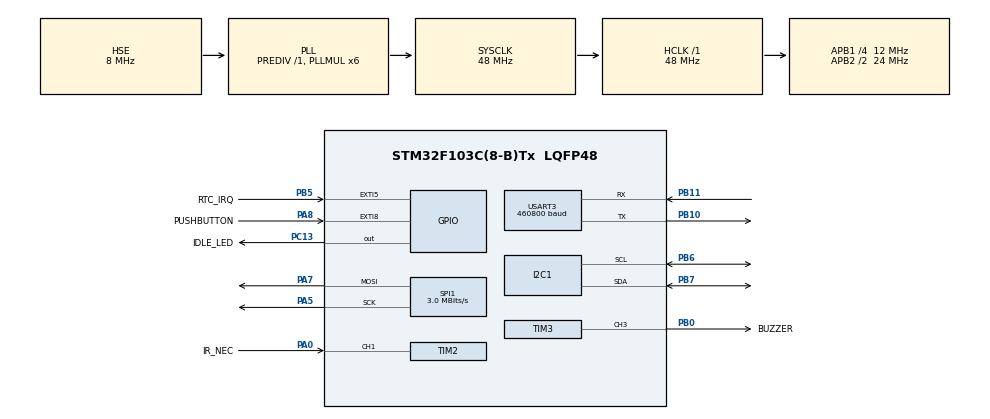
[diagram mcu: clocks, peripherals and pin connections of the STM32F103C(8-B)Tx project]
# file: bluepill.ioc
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Mcu.Family=STM32F1
NVIC.USART3_IRQn=true\:7\:0\:true\:false\:true\:true\:true
Dma.SPI1_TX.0.MemInc=DMA_MINC_ENABLE
Dma.SPI1_TX.0.PeriphInc=DMA_PINC_DISABLE
TIM2.Channel-Input_Capture1_from_TI1=TIM_CHANNEL_1
NVIC.DMA1_Channel5_IRQn=true\:4\:0\:true\:false\:true\:false\:true
SPI1.VirtualType=VM_MASTER
PB10.Mode=Asynchronous
VP_IWDG_VS_IWDG.Mode=IWDG_Activate
PB0.GPIO_Label=BUZZER
PB11.Signal=USART3_RX
RCC.SYSCLKSource=RCC_SYSCLKSOURCE_PLLCLK
ProjectManager.StackSize=0x400
PD1-OSC_OUT.Signal=RCC_OSC_OUT
NVIC.DMA1_Channel3_IRQn=true\:5\:0\:true\:false\:true\:false\:true
USART3.BaudRate=460800
TIM2.ICPolarity_CH1=TIM_INPUTCHANNELPOLARITY_FALLING
Dma.TIM2_CH1.1.Direction=DMA_PERIPH_TO_MEMORY
SPI1.Direction=SPI_DIRECTION_2LINES
RCC.HCLKFreq_Value=48000000
RCC.APB2TimFreq_Value=48000000
TIM3.Period=28-1
PB6.Signal=I2C1_SCL
PB6.Mode=I2C
SPI1.CalculateBaudRate=3.0 MBits/s
Dma.TIM3_CH3.2.MemDataAlignment=DMA_MDATAALIGN_BYTE
RCC.AHBFreq_Value=48000000
RCC.PLLMUL=RCC_PLL_MUL6
PA14.Mode=Serial_Wire
TIM3.Prescaler=4-1
NVIC.TIM2_IRQn=true\:3\:0\:true\:false\:true\:true\:true
PA0-WKUP.GPIO_Mode=GPIO_MODE_INPUT
PB7.Signal=I2C1_SDA
PA8.Signal=GPXTI8
Dma.TIM3_CH3.2.MemInc=DMA_MINC_ENABLE
Dma.SPI1_TX.0.Mode=DMA_NORMAL
Mcu.Package=LQFP48
TIM2.Prescaler=23
Dma.TIM2_CH1.1.MemDataAlignment=DMA_MDATAALIGN_WORD
PA8.GPIO_ModeDefaultEXTI=GPIO_MODE_IT_FALLING
Dma.TIM2_CH1.1.Priority=DMA_PRIORITY_LOW
RCC.APB2CLKDivider=RCC_HCLK_DIV2
PB5.GPIO_Label=RTC_IRQ
Dma.Request2=TIM3_CH3
Dma.Request1=TIM2_CH1
Dma.TIM3_CH3.2.Mode=DMA_NORMAL
RCC.APB1TimFreq_Value=24000000
Dma.TIM2_CH1.1.PeriphDataAlignment=DMA_PDATAALIGN_WORD
Dma.Request0=SPI1_TX
SPI1.BaudRatePrescaler=SPI_BAUDRATEPRESCALER_8
VP_TIM3_VS_ClockSourceINT.Mode=Internal
PA5.Mode=TX_Only_Simplex_Unidirect_Master
RCC.PLLSourceVirtual=RCC_PLLSOURCE_HSE
Dma.TIM2_CH1.1.MemInc=DMA_MINC_ENABLE
Dma.TIM3_CH3.2.Direction=DMA_MEMORY_TO_PERIPH
PA7.Mode=TX_Only_Simplex_Unidirect_Master
PD1-OSC_OUT.Mode=HSE-External-Oscillator
VP_TIM2_VS_ControllerModeReset.Mode=Reset Mode
PC13-TAMPER-RTC.Signal=GPIO_Output
PD0-OSC_IN.Signal=RCC_OSC_IN
RCC.APB1CLKDivider=RCC_HCLK_DIV4
SH.S_TIM3_CH3.0=TIM3_CH3,PWM Generation3 CH3
PA0-WKUP.GPIO_Label=IR_NEC
PA0-WKUP.Signal=S_TIM2_CH1_ETR
PA13.Signal=SYS_JTMS-SWDIO
TIM3.Channel-PWM\ Generation3\ CH3=TIM_CHANNEL_3
PA8.GPIO_Label=PUSHBUTTON
Dma.TIM2_CH1.1.Instance=DMA1_Channel5
PB11.Mode=Asynchronous
NVIC.DMA1_Channel2_IRQn=true\:0\:0\:false\:false\:true\:false\:true
ProjectManager.TargetToolchain=Makefile
I2C1.I2C_Mode=I2C_Fast
Dma.SPI1_TX.0.PeriphDataAlignment=DMA_PDATAALIGN_BYTE
Dma.SPI1_TX.0.Direction=DMA_MEMORY_TO_PERIPH
TIM2.ICFilter_CH1=4
RCC.USBFreq_Value=48000000
Dma.TIM3_CH3.2.Instance=DMA1_Channel2
PD0-OSC_IN.Mode=HSE-External-Oscillator
PB10.Signal=USART3_TX
PA5.Signal=SPI1_SCK
board=custom
PB0.GPIO_ModeDefaultPP=GPIO_MODE_AF_PP
PC13-TAMPER-RTC.GPIO_Label=IDLE_LED
RCC.APB2Freq_Value=24000000
Dma.TIM2_CH1.1.PeriphInc=DMA_PINC_DISABLE
VP_TIM2_VS_ClockSourceINT.Mode=Internal
SPI1.Mode=SPI_MODE_MASTER
Dma.SPI1_TX.0.Instance=DMA1_Channel3
TIM2.Period=0xFFFF
PA13.Mode=Serial_Wire
Mcu.Name=STM32F103C(8-B)Tx
RCC.SYSCLKFreq_VALUE=48000000
PB5.Signal=GPXTI5
USART3.VirtualMode=VM_ASYNC
PB5.GPIO_PuPd=GPIO_PULLUP
Dma.TIM3_CH3.2.Priority=DMA_PRIORITY_LOW
PB7.Mode=I2C
SH.S_TIM2_CH1_ETR.1=TIM2_CH1,Input_Capture1_from_TI1
SH.S_TIM2_CH1_ETR.0=TIM2_CH1,TriggerSource_TI1FP1
NVIC.EXTI9_5_IRQn=true\:0\:0\:false\:false\:true\:true\:true
PA14.Signal=SYS_JTCK-SWCLK
ProjectManager.HeapSize=0x200
Dma.SPI1_TX.0.MemDataAlignment=DMA_MDATAALIGN_BYTE
Dma.SPI1_TX.0.Priority=DMA_PRIORITY_LOW
Dma.TIM2_CH1.1.Mode=DMA_NORMAL
PA8.GPIO_PuPd=GPIO_PULLUP
NVIC.PriorityGroup=NVIC_PRIORITYGROUP_4
IWDG.Prescaler=IWDG_PRESCALER_16
Dma.TIM3_CH3.2.PeriphInc=DMA_PINC_DISABLE
PA0-WKUP.GPIO_PuPd=GPIO_PULLUP
RCC.APB1Freq_Value=12000000
PB0.Signal=S_TIM3_CH3
Dma.TIM3_CH3.2.PeriphDataAlignment=DMA_PDATAALIGN_HALFWORD
PA7.Signal=SPI1_MOSI

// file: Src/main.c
/* USER CODE BEGIN Header */
/**
  ******************************************************************************
  * @file           : main.c
  * @brief          : Main program body
  ******************************************************************************
  * @attention
  *
  * <h2><center>&copy; Copyright (c) 2019 STMicroelectronics.
  * All rights reserved.</center></h2>
  *
  * This software component is licensed by ST under BSD 3-Clause license,
  * the "License"; You may not use this file except in compliance with the
  * License. You may obtain a copy of the License at:
  *                        opensource.org/licenses/BSD-3-Clause
  *
  ******************************************************************************
  */
/* USER CODE END Header */
#include "main.h"

/* USER CODE BEGIN Includes */
#include <string.h>
#include "esm/esm.h"
#include "board.h"
/* USER CODE END Includes */

I2C_HandleTypeDef hi2c1;

IWDG_HandleTypeDef hiwdg;

SPI_HandleTypeDef hspi1;
DMA_HandleTypeDef hdma_spi1_tx;

TIM_HandleTypeDef htim2;
TIM_HandleTypeDef htim3;
DMA_HandleTypeDef hdma_tim2_ch1;
DMA_HandleTypeDef hdma_tim3_ch3;

UART_HandleTypeDef huart3;

void SystemClock_Config(void);
static void MX_GPIO_Init(void);
static void MX_DMA_Init(void);
static void MX_SPI1_Init(void);
static void MX_USART3_UART_Init(void);
static void MX_I2C1_Init(void);
static void MX_TIM2_Init(void);
static void MX_TIM3_Init(void);
static void MX_IWDG_Init(void);

int main(void)
{

  /* MCU Configuration--------------------------------------------------------*/

  /* Reset of all peripherals, Initializes the Flash interface and the Systick. */
  HAL_Init();

  /* Configure the system clock */
  SystemClock_Config();

  /* Initialize all configured peripherals */
  MX_GPIO_Init();
  MX_DMA_Init();
  MX_SPI1_Init();
  MX_USART3_UART_Init();
  MX_I2C1_Init();
  MX_TIM2_Init();
  MX_TIM3_Init();
  MX_IWDG_Init();

  /* Infinite loop */
  /* USER CODE BEGIN WHILE */
  while (1)
  {
    esm_process();
    /* USER CODE END WHILE */

  }
}

void SystemClock_Config(void)
{
  RCC_OscInitTypeDef RCC_OscInitStruct = {0};
  RCC_ClkInitTypeDef RCC_ClkInitStruct = {0};

  /** Initializes the RCC Oscillators according to the specified parameters
  * in the RCC_OscInitTypeDef structure.
  */
  RCC_OscInitStruct.OscillatorType = RCC_OSCILLATORTYPE_LSI|RCC_OSCILLATORTYPE_HSE;
  RCC_OscInitStruct.HSEState = RCC_HSE_ON;
  RCC_OscInitStruct.HSEPredivValue = RCC_HSE_PREDIV_DIV1;
  RCC_OscInitStruct.HSIState = RCC_HSI_ON;
  RCC_OscInitStruct.LSIState = RCC_LSI_ON;
  RCC_OscInitStruct.PLL.PLLState = RCC_PLL_ON;
  RCC_OscInitStruct.PLL.PLLSource = RCC_PLLSOURCE_HSE;
  RCC_OscInitStruct.PLL.PLLMUL = RCC_PLL_MUL6;
  if (HAL_RCC_OscConfig(&RCC_OscInitStruct) != HAL_OK)
  {
    Error_Handler();
  }
  /** Initializes the CPU, AHB and APB buses clocks
  */
  RCC_ClkInitStruct.ClockType = RCC_CLOCKTYPE_HCLK|RCC_CLOCKTYPE_SYSCLK
                              |RCC_CLOCKTYPE_PCLK1|RCC_CLOCKTYPE_PCLK2;
  RCC_ClkInitStruct.SYSCLKSource = RCC_SYSCLKSOURCE_PLLCLK;
  RCC_ClkInitStruct.AHBCLKDivider = RCC_SYSCLK_DIV1;
  RCC_ClkInitStruct.APB1CLKDivider = RCC_HCLK_DIV4;
  RCC_ClkInitStruct.APB2CLKDivider = RCC_HCLK_DIV2;

  if (HAL_RCC_ClockConfig(&RCC_ClkInitStruct, FLASH_LATENCY_1) != HAL_OK)
  {
    Error_Handler();
  }
}

static void MX_I2C1_Init(void)
{

  hi2c1.Instance = I2C1;
  hi2c1.Init.ClockSpeed = 400000;
  hi2c1.Init.DutyCycle = I2C_DUTYCYCLE_2;
  hi2c1.Init.OwnAddress1 = 0;
  hi2c1.Init.AddressingMode = I2C_ADDRESSINGMODE_7BIT;
  hi2c1.Init.DualAddressMode = I2C_DUALADDRESS_DISABLE;
  hi2c1.Init.OwnAddress2 = 0;
  hi2c1.Init.GeneralCallMode = I2C_GENERALCALL_DISABLE;
  hi2c1.Init.NoStretchMode = I2C_NOSTRETCH_DISABLE;
  if (HAL_I2C_Init(&hi2c1) != HAL_OK)
  {
    Error_Handler();
  }

}

static void MX_IWDG_Init(void)
{

  hiwdg.Instance = IWDG;
  hiwdg.Init.Prescaler = IWDG_PRESCALER_16;
  hiwdg.Init.Reload = 4095;
  if (HAL_IWDG_Init(&hiwdg) != HAL_OK)
  {
    Error_Handler();
  }

}

static void MX_SPI1_Init(void)
{

  /* SPI1 parameter configuration*/
  hspi1.Instance = SPI1;
  hspi1.Init.Mode = SPI_MODE_MASTER;
  hspi1.Init.Direction = SPI_DIRECTION_2LINES;
  hspi1.Init.DataSize = SPI_DATASIZE_8BIT;
  hspi1.Init.CLKPolarity = SPI_POLARITY_LOW;
  hspi1.Init.CLKPhase = SPI_PHASE_1EDGE;
  hspi1.Init.NSS = SPI_NSS_SOFT;
  hspi1.Init.BaudRatePrescaler = SPI_BAUDRATEPRESCALER_8;
  hspi1.Init.FirstBit = SPI_FIRSTBIT_MSB;
  hspi1.Init.TIMode = SPI_TIMODE_DISABLE;
  hspi1.Init.CRCCalculation = SPI_CRCCALCULATION_DISABLE;
  hspi1.Init.CRCPolynomial = 10;
  if (HAL_SPI_Init(&hspi1) != HAL_OK)
  {
    Error_Handler();
  }

}

static void MX_TIM2_Init(void)
{

  TIM_ClockConfigTypeDef sClockSourceConfig = {0};
  TIM_SlaveConfigTypeDef sSlaveConfig = {0};
  TIM_MasterConfigTypeDef sMasterConfig = {0};
  TIM_IC_InitTypeDef sConfigIC = {0};

  htim2.Instance = TIM2;
  htim2.Init.Prescaler = 23;
  htim2.Init.CounterMode = TIM_COUNTERMODE_UP;
  htim2.Init.Period = 0xFFFF;
  htim2.Init.ClockDivision = TIM_CLOCKDIVISION_DIV1;
  htim2.Init.AutoReloadPreload = TIM_AUTORELOAD_PRELOAD_DISABLE;
  if (HAL_TIM_Base_Init(&htim2) != HAL_OK)
  {
    Error_Handler();
  }
  sClockSourceConfig.ClockSource = TIM_CLOCKSOURCE_INTERNAL;
  if (HAL_TIM_ConfigClockSource(&htim2, &sClockSourceConfig) != HAL_OK)
  {
    Error_Handler();
  }
  if (HAL_TIM_IC_Init(&htim2) != HAL_OK)
  {
    Error_Handler();
  }
  sSlaveConfig.SlaveMode = TIM_SLAVEMODE_RESET;
  sSlaveConfig.InputTrigger = TIM_TS_TI1FP1;
  sSlaveConfig.TriggerPolarity = TIM_INPUTCHANNELPOLARITY_FALLING;
  sSlaveConfig.TriggerFilter = 0;
  if (HAL_TIM_SlaveConfigSynchro(&htim2, &sSlaveConfig) != HAL_OK)
  {
    Error_Handler();
  }
  sMasterConfig.MasterOutputTrigger = TIM_TRGO_RESET;
  sMasterConfig.MasterSlaveMode = TIM_MASTERSLAVEMODE_DISABLE;
  if (HAL_TIMEx_MasterConfigSynchronization(&htim2, &sMasterConfig) != HAL_OK)
  {
    Error_Handler();
  }
  sConfigIC.ICPolarity = TIM_INPUTCHANNELPOLARITY_FALLING;
  sConfigIC.ICSelection = TIM_ICSELECTION_DIRECTTI;
  sConfigIC.ICPrescaler = TIM_ICPSC_DIV1;
  sConfigIC.ICFilter = 4;
  if (HAL_TIM_IC_ConfigChannel(&htim2, &sConfigIC, TIM_CHANNEL_1) != HAL_OK)
  {
    Error_Handler();
  }

}

static void MX_TIM3_Init(void)
{

  TIM_ClockConfigTypeDef sClockSourceConfig = {0};
  TIM_MasterConfigTypeDef sMasterConfig = {0};
  TIM_OC_InitTypeDef sConfigOC = {0};

  htim3.Instance = TIM3;
  htim3.Init.Prescaler = 4-1;
  htim3.Init.CounterMode = TIM_COUNTERMODE_UP;
  htim3.Init.Period = 28-1;
  htim3.Init.ClockDivision = TIM_CLOCKDIVISION_DIV1;
  htim3.Init.AutoReloadPreload = TIM_AUTORELOAD_PRELOAD_DISABLE;
  if (HAL_TIM_Base_Init(&htim3) != HAL_OK)
  {
    Error_Handler();
  }
  sClockSourceConfig.ClockSource = TIM_CLOCKSOURCE_INTERNAL;
  if (HAL_TIM_ConfigClockSource(&htim3, &sClockSourceConfig) != HAL_OK)
  {
    Error_Handler();
  }
  if (HAL_TIM_PWM_Init(&htim3) != HAL_OK)
  {
    Error_Handler();
  }
  sMasterConfig.MasterOutputTrigger = TIM_TRGO_RESET;
  sMasterConfig.MasterSlaveMode = TIM_MASTERSLAVEMODE_DISABLE;
  if (HAL_TIMEx_MasterConfigSynchronization(&htim3, &sMasterConfig) != HAL_OK)
  {
    Error_Handler();
  }
  sConfigOC.OCMode = TIM_OCMODE_PWM1;
  sConfigOC.Pulse = 0;
  sConfigOC.OCPolarity = TIM_OCPOLARITY_HIGH;
  sConfigOC.OCFastMode = TIM_OCFAST_DISABLE;
  if (HAL_TIM_PWM_ConfigChannel(&htim3, &sConfigOC, TIM_CHANNEL_3) != HAL_OK)
  {
    Error_Handler();
  }
  /* USER CODE BEGIN TIM3_Init 2 */
  htim3.Instance->CCR3 = 64;
  /* USER CODE END TIM3_Init 2 */
  HAL_TIM_MspPostInit(&htim3);

}

static void MX_USART3_UART_Init(void)
{

  huart3.Instance = USART3;
  huart3.Init.BaudRate = 460800;
  huart3.Init.WordLength = UART_WORDLENGTH_8B;
  huart3.Init.StopBits = UART_STOPBITS_1;
  huart3.Init.Parity = UART_PARITY_NONE;
  huart3.Init.Mode = UART_MODE_TX_RX;
  huart3.Init.HwFlowCtl = UART_HWCONTROL_NONE;
  huart3.Init.OverSampling = UART_OVERSAMPLING_16;
  if (HAL_UART_Init(&huart3) != HAL_OK)
  {
    Error_Handler();
  }

}

static void MX_DMA_Init(void)
{

  /* DMA controller clock enable */
  __HAL_RCC_DMA1_CLK_ENABLE();

  /* DMA interrupt init */
  /* DMA1_Channel2_IRQn interrupt configuration */
  HAL_NVIC_SetPriority(DMA1_Channel2_IRQn, 0, 0);
  HAL_NVIC_EnableIRQ(DMA1_Channel2_IRQn);
  /* DMA1_Channel3_IRQn interrupt configuration */
  HAL_NVIC_SetPriority(DMA1_Channel3_IRQn, 5, 0);
  HAL_NVIC_EnableIRQ(DMA1_Channel3_IRQn);
  /* DMA1_Channel5_IRQn interrupt configuration */
  HAL_NVIC_SetPriority(DMA1_Channel5_IRQn, 4, 0);
  HAL_NVIC_EnableIRQ(DMA1_Channel5_IRQn);

}

static void MX_GPIO_Init(void)
{
  GPIO_InitTypeDef GPIO_InitStruct = {0};

  /* GPIO Ports Clock Enable */
  __HAL_RCC_GPIOC_CLK_ENABLE();
  __HAL_RCC_GPIOD_CLK_ENABLE();
  __HAL_RCC_GPIOA_CLK_ENABLE();
  __HAL_RCC_GPIOB_CLK_ENABLE();

  /*Configure GPIO pin Output Level */
  HAL_GPIO_WritePin(IDLE_LED_GPIO_Port, IDLE_LED_Pin, GPIO_PIN_RESET);

  /*Configure GPIO pin : IDLE_LED_Pin */
  GPIO_InitStruct.Pin = IDLE_LED_Pin;
  GPIO_InitStruct.Mode = GPIO_MODE_OUTPUT_PP;
  GPIO_InitStruct.Pull = GPIO_NOPULL;
  GPIO_InitStruct.Speed = GPIO_SPEED_FREQ_LOW;
  HAL_GPIO_Init(IDLE_LED_GPIO_Port, &GPIO_InitStruct);

  /*Configure GPIO pin : PUSHBUTTON_Pin */
  GPIO_InitStruct.Pin = PUSHBUTTON_Pin;
  GPIO_InitStruct.Mode = GPIO_MODE_IT_FALLING;
  GPIO_InitStruct.Pull = GPIO_PULLUP;
  HAL_GPIO_Init(PUSHBUTTON_GPIO_Port, &GPIO_InitStruct);

  /*Configure GPIO pin : RTC_IRQ_Pin */
  GPIO_InitStruct.Pin = RTC_IRQ_Pin;
  GPIO_InitStruct.Mode = GPIO_MODE_IT_RISING;
  GPIO_InitStruct.Pull = GPIO_PULLUP;
  HAL_GPIO_Init(RTC_IRQ_GPIO_Port, &GPIO_InitStruct);

  /* EXTI interrupt init*/
  HAL_NVIC_SetPriority(EXTI9_5_IRQn, 0, 0);
  HAL_NVIC_EnableIRQ(EXTI9_5_IRQn);

}

void Error_Handler(void)
{
}

/************************ (C) COPYRIGHT STMicroelectronics *****END OF FILE****/
